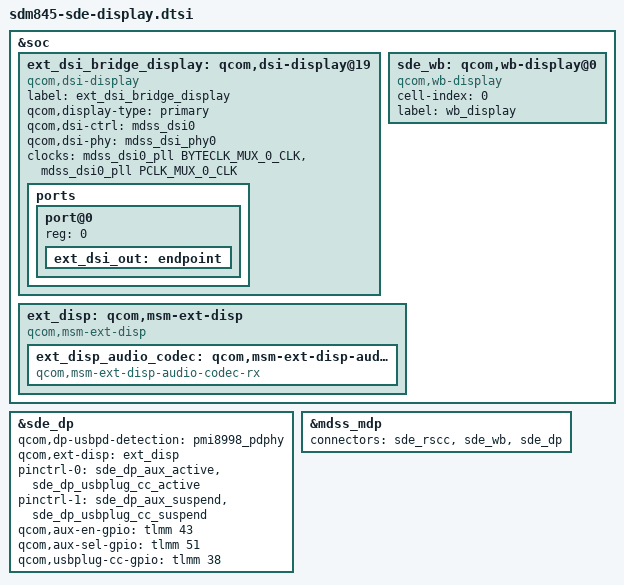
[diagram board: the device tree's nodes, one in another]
/* Copyright (c) 2016-2019, The Linux Foundation. All rights reserved.
 * Copyright (C) 2019 XiaoMi, Inc.
 *
 * This program is free software; you can redistribute it and/or modify
 * it under the terms of the GNU General Public License version 2 and
 * only version 2 as published by the Free Software Foundation.
 *
 * This program is distributed in the hope that it will be useful,
 * but WITHOUT ANY WARRANTY; without even the implied warranty of
 * MERCHANTABILITY or FITNESS FOR A PARTICULAR PURPOSE.  See the
 * GNU General Public License for more details.
 */

#include <dt-bindings/clock/mdss-10nm-pll-clk.h>

&soc {
	ext_dsi_bridge_display: qcom,dsi-display@19 {
		compatible = "qcom,dsi-display";
		label = "ext_dsi_bridge_display";
		qcom,display-type = "primary";

		qcom,dsi-ctrl = <&mdss_dsi0>;
		qcom,dsi-phy = <&mdss_dsi_phy0>;
		clocks = <&mdss_dsi0_pll BYTECLK_MUX_0_CLK>,
		       <&mdss_dsi0_pll PCLK_MUX_0_CLK>;
		clock-names = "mux_byte_clk", "mux_pixel_clk";

		ports {
			#address-cells = <1>;
			#size-cells = <0>;

			port@0 {
				reg = <0>;
				ext_dsi_out: endpoint {
				};
			};
		};
	};

	sde_wb: qcom,wb-display@0 {
		compatible = "qcom,wb-display";
		cell-index = <0>;
		label = "wb_display";
	};

	ext_disp: qcom,msm-ext-disp {
		compatible = "qcom,msm-ext-disp";

		ext_disp_audio_codec: qcom,msm-ext-disp-audio-codec-rx {
			compatible = "qcom,msm-ext-disp-audio-codec-rx";
		};
	};
};

&sde_dp {
	qcom,dp-usbpd-detection = <&pmi8998_pdphy>;
	qcom,ext-disp = <&ext_disp>;

	pinctrl-names = "mdss_dp_active", "mdss_dp_sleep";
	pinctrl-0 = <&sde_dp_aux_active &sde_dp_usbplug_cc_active>;
	pinctrl-1 = <&sde_dp_aux_suspend &sde_dp_usbplug_cc_suspend>;
	qcom,aux-en-gpio = <&tlmm 43 0>;
	qcom,aux-sel-gpio = <&tlmm 51 0>;
	qcom,usbplug-cc-gpio = <&tlmm 38 0>;
};

&mdss_mdp {
	connectors = <&sde_rscc &sde_wb &sde_dp>;
};
